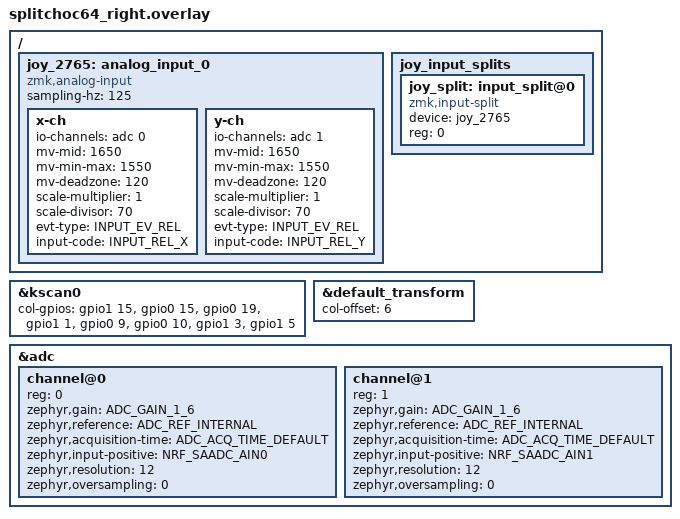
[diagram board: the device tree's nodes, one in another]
#include <zephyr/dt-bindings/input/input-event-codes.h>
#include <zephyr/dt-bindings/adc/adc.h>
#include <zephyr/dt-bindings/adc/nrf-saadc.h>

#include "splitchoc64.dtsi"

&kscan0 {
    /* RIGHT Ver012: COL0..7 = D10,D11,D12,D13,D14,D15,D17,D18 */
    col-gpios
        = <&gpio1 15 GPIO_ACTIVE_HIGH>
        , <&gpio0 15 GPIO_ACTIVE_HIGH>
        , <&gpio0 19 GPIO_ACTIVE_HIGH>
        , <&gpio1 1 GPIO_ACTIVE_HIGH>
        , <&gpio0 9 GPIO_ACTIVE_HIGH>
        , <&gpio0 10 GPIO_ACTIVE_HIGH>
        , <&gpio1 3 GPIO_ACTIVE_HIGH>
        , <&gpio1 5 GPIO_ACTIVE_HIGH>
        ;
};

&default_transform {
    /* LEFT uses six matrix columns, so RIGHT begins at global column 6. */
    col-offset = <6>;
};

&adc {
    status = "okay";
    #address-cells = <1>;
    #size-cells = <0>;

    channel@0 {
        reg = <0>;
        zephyr,gain = "ADC_GAIN_1_6";
        zephyr,reference = "ADC_REF_INTERNAL";
        zephyr,acquisition-time = <ADC_ACQ_TIME_DEFAULT>;
        zephyr,input-positive = <NRF_SAADC_AIN0>; /* P0.02 / J4-3 / JOY_X */
        zephyr,resolution = <12>;
        zephyr,oversampling = <0>;
    };

    channel@1 {
        reg = <1>;
        zephyr,gain = "ADC_GAIN_1_6";
        zephyr,reference = "ADC_REF_INTERNAL";
        zephyr,acquisition-time = <ADC_ACQ_TIME_DEFAULT>;
        zephyr,input-positive = <NRF_SAADC_AIN1>; /* P0.03 / J4-4 / JOY_Y */
        zephyr,resolution = <12>;
        zephyr,oversampling = <0>;
    };
};

/ {
    joy_2765: analog_input_0 {
        compatible = "zmk,analog-input";
        sampling-hz = <125>;

        x-ch {
            io-channels = <&adc 0>;
            mv-mid = <1650>;
            mv-min-max = <1550>;
            mv-deadzone = <120>;
            scale-multiplier = <1>;
            scale-divisor = <70>;
            evt-type = <INPUT_EV_REL>;
            input-code = <INPUT_REL_X>;
        };

        y-ch {
            io-channels = <&adc 1>;
            mv-mid = <1650>;
            mv-min-max = <1550>;
            mv-deadzone = <120>;
            scale-multiplier = <1>;
            scale-divisor = <70>;
            evt-type = <INPUT_EV_REL>;
            input-code = <INPUT_REL_Y>;
        };
    };

    joy_input_splits {
        #address-cells = <1>;
        #size-cells = <0>;

        joy_split: input_split@0 {
            compatible = "zmk,input-split";
            device = <&joy_2765>;
            reg = <0>;
        };
    };
};
